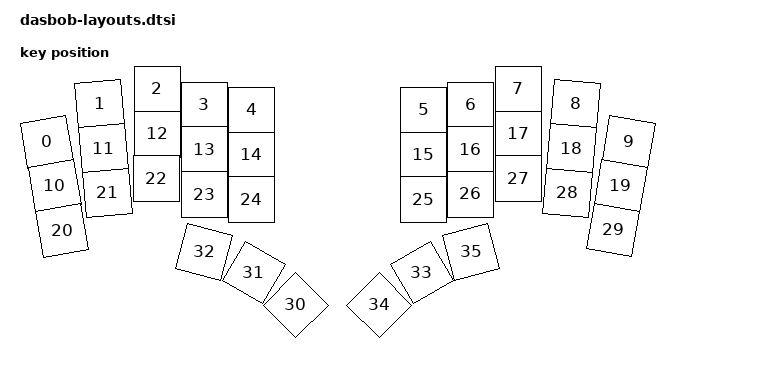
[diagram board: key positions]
#include <physical_layouts.dtsi>

// this file has been generated by
// 1. importing the DASBOB kicad PCB files into https://nickcoutsos.github.io/keymap-layout-tools/
// 2. fix order via: reorder -> clear all -> assign all keys to row 0 and column 0
// 3. copy JSON description and paste into https://zmk-physical-layout-converter.streamlit.app/
// 4. copy ZMK DTS from 2nd column, remove parts already present in dasbob.dtsi file and paste remainder below

/ {
    physical_layout0: physical_layout_0 {
        compatible = "zmk,physical-layout";
        display-name = "DASBOB";

        // https://zmk.dev/docs/development/hardware-integration/physical-layouts
        // this array of key descriptions needs to be listed in the same order as keymap bindings and matrix transforms
        keys  //                     w   h    x    y     rot    rx    ry
            = <&key_physical_attrs 100 100    0  106 (-1000)    50   156>
            , <&key_physical_attrs 100 100  106   30  (-500)   156    80>
            , <&key_physical_attrs 100 100  221    0       0     0     0>
            , <&key_physical_attrs 100 100  315   32       0     0     0>
            , <&key_physical_attrs 100 100  410   42       0     0     0>
            , <&key_physical_attrs 100 100  754   42       0     0     0>
            , <&key_physical_attrs 100 100  848   32       0     0     0>
            , <&key_physical_attrs 100 100  943    0       0     0     0>
            , <&key_physical_attrs 100 100 1058   30     500  1108    80>
            , <&key_physical_attrs 100 100 1164  106    1000  1214   156>
            , <&key_physical_attrs 100 100   16  194 (-1000)    66   244>
            , <&key_physical_attrs 100 100  113  119  (-500)   163   169>
            , <&key_physical_attrs 100 100  221   90       0     0     0>
            , <&key_physical_attrs 100 100  315  121       0     0     0>
            , <&key_physical_attrs 100 100  410  132       0     0     0>
            , <&key_physical_attrs 100 100  754  132       0     0     0>
            , <&key_physical_attrs 100 100  848  121       0     0     0>
            , <&key_physical_attrs 100 100  943   90       0     0     0>
            , <&key_physical_attrs 100 100 1050  119     500  1100   169>
            , <&key_physical_attrs 100 100 1148  194    1000  1198   244>
            , <&key_physical_attrs 100 100   31  283 (-1000)    81   333>
            , <&key_physical_attrs 100 100  121  208  (-500)   171   258>
            , <&key_physical_attrs 100 100  220  179       0     0     0>
            , <&key_physical_attrs 100 100  315  211       0     0     0>
            , <&key_physical_attrs 100 100  410  221       0     0     0>
            , <&key_physical_attrs 100 100  754  221       0     0     0>
            , <&key_physical_attrs 100 100  848  210       0     0     0>
            , <&key_physical_attrs 100 100  943  179       0     0     0>
            , <&key_physical_attrs 100 100 1042  208     500  1092   258>
            , <&key_physical_attrs 100 100 1133  282    1000  1183   332>
            , <&key_physical_attrs 100 100  498  432    4500   548   482>
            , <&key_physical_attrs 100 100  414  367    3000   464   417>
            , <&key_physical_attrs 100 100  315  326    1500   365   376>
            , <&key_physical_attrs 100 100  750  367 (-3000)   800   417>
            , <&key_physical_attrs 100 100  665  432 (-4500)   715   482>
            , <&key_physical_attrs 100 100  849  326 (-1500)   899   376>
            ;
    };
};
